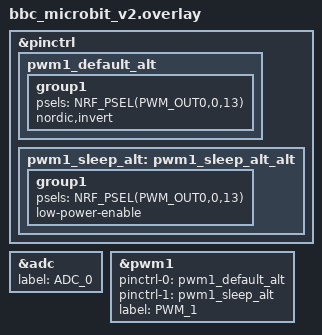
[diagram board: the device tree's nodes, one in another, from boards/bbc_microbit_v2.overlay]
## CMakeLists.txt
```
# SPDX-License-Identifier: Apache-2.0

cmake_minimum_required(VERSION 3.20.0)
find_package(Zephyr REQUIRED HINTS $ENV{ZEPHYR_BASE})
project(peripheral)


# Automatically include all .c files in the src directory
file(GLOB APP_SOURCES "src/*.c")

target_sources(app PRIVATE
  ${APP_SOURCES}
)
```

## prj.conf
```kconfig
# Increased stack due to settings API usage
CONFIG_SYSTEM_WORKQUEUE_STACK_SIZE=2048

CONFIG_BT=y
CONFIG_LOG=y
CONFIG_BT_SMP=y
CONFIG_BT_SIGNING=y
CONFIG_BT_PERIPHERAL=y
CONFIG_BT_DIS=y
CONFIG_BT_ATT_PREPARE_COUNT=5
CONFIG_BT_PRIVACY=y
CONFIG_BT_DEVICE_NAME="Fish Feeder"
CONFIG_BT_DEVICE_APPEARANCE=833
CONFIG_BT_DEVICE_NAME_DYNAMIC=y
CONFIG_BT_DEVICE_NAME_MAX=65

CONFIG_BT_KEYS_OVERWRITE_OLDEST=y
CONFIG_BT_SETTINGS=y
CONFIG_FLASH=y
CONFIG_FLASH_MAP=y
CONFIG_NVS=y
CONFIG_SETTINGS=y

CONFIG_GPIO=y

CONFIG_SERIAL=y
CONFIG_CONSOLE=y
CONFIG_UART_CONSOLE=y

CONFIG_NFCT_PINS_AS_GPIOS=y

CONFIG_CBPRINTF_FP_SUPPORT=y

CONFIG_PWM=y
CONFIG_ADC=y
CONFIG_NRFX_SAADC=y

CONFIG_DISPLAY=y
```

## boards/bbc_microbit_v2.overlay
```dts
&pinctrl {
    pwm1_default_alt: pwm1_default_alt {
        group1  {
            psels = <NRF_PSEL(PWM_OUT0,0,13)>;
            nordic,invert;
        };
    };
    pwm1_sleep_alt: pwm1_sleep_alt_alt {
        group1  {
            psels = <NRF_PSEL(PWM_OUT0,0,13)>;
            low-power-enable;
        };
    };
};

&adc {
	status = "okay";
    label = "ADC_0";
};

&pwm1 {
	status = "okay";
    pinctrl-0 = <&pwm1_default_alt>;
    pinctrl-1 = <&pwm1_sleep_alt>;
    pinctrl-names = "default", "sleep";

    label="PWM_1";
};
```

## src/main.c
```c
#include "pin_defs.h"
#include "ultrasonic.h"
#include <zephyr/kernel.h>
#include <zephyr/device.h>
#include <zephyr/drivers/gpio.h>
#include <stdio.h>
#include "info.h"
#include "timer.h"
#include "pwm.h"
#include "adc.h"
#include "display.h"
#include "ble.h"

#define THREAD_STACK_SIZE 1024  // Adjust based on usage
#define THREAD_PRIORITY 5       // Higher number = lower priority
#define ADC_THRESHOLD 100

K_THREAD_STACK_DEFINE(adc_thread_stack, THREAD_STACK_SIZE);
static struct k_thread adc_thread_data;

K_THREAD_STACK_DEFINE(timer_feed_thread_stack, THREAD_STACK_SIZE);
static struct k_thread timer_feed_thread_data;

K_THREAD_STACK_DEFINE(food_level_thread_stack, THREAD_STACK_SIZE);
static struct k_thread food_level_thread_data;

void adc_thread(void* p1, void* p2, void* p3) {
	bool has_pwm_lock = false;
	bool has_disp_lock = false;
	while (1) {
		int val = adcread();
		if (val > ADC_THRESHOLD) {
			// set duty to something
			// if (has_lock) {
			// 	pwm_set_duty((float)val / 4096.0f);
			// } else if (pwm_lock(100) == 0) {
			// 	has_lock = true;
			// 	pwm_set_duty((float)val / 4096.0f);
			// } else {
			// 	has_lock = false;
			// }
			if (!has_pwm_lock) {
				if (pwm_lock(100) == 0) {
					has_pwm_lock = true;
				}
			}
			if (has_pwm_lock) {
				float percentage = (float)val / 4096.0f;
				pwm_set_duty(percentage);

				if (!has_disp_lock) {
					if (display_lock() == 0) {
						has_disp_lock = true;
					}
				}
				if (has_disp_lock) {
					write_row_pattern((int)(percentage * 25));
				}
			}
		} else {
			// set duty to 0
			if (has_pwm_lock) {
				pwm_set_duty(0);
				pwm_unlock();
				has_pwm_lock = false;
			}
			if (has_disp_lock) {
				write_row_pattern(0);
				display_unlock();
				has_disp_lock = false;
			}
		}
		k_sleep(K_MSEC(100));
	}
}

void timer_feed_thread(void* p1, void* p2, void* p3) {
	info_t* info = get_info();
	while (1) {
		k_mutex_lock(info->mut, K_FOREVER);
		uint32_t cur_time = read_timer_s();
		uint32_t next_feed_time = info->_next_feed_timestamp_sec;
		uint32_t feed_dur = info->feed_duration_sec;
		// fprintf(stderr, "next feed time: %d, current time %d\n", next_feed_time, cur_time);
		k_mutex_unlock(info->mut);

		if (cur_time >= next_feed_time) {
			// feed
			if (pwm_lock(1) == 0) {
				fprintf(stderr, "Feeding for %d seconds\n", feed_dur);
				pwm_set_duty(0.5);
				k_sleep(K_SECONDS(feed_dur));
				pwm_set_duty(0);
				pwm_unlock();
			} else {
				fprintf(stderr, "timer feed:Failed to lock PWM\n");
				k_sleep(K_SECONDS(feed_dur));
			}

			k_mutex_lock(info->mut, K_FOREVER);
			info->_last_feed_timestamp_sec = cur_time;
			info->_next_feed_timestamp_sec = cur_time + info->feed_freq_sec;
			k_mutex_unlock(info->mut);
		}

		k_sleep(K_MSEC(100));
	}
}

void food_level_thread(void* p1, void* p2, void* p3) {
	info_t* info = get_info();
	while (1) {
		// check food level
		double distance = sample_sensors_distance_cm();
		fprintf(stderr, "Distance: %f\n", distance);

		k_mutex_lock(info->mut, K_FOREVER);
		info->is_food_low = distance >= 15.0;
		bt_gatt_notify(NULL, &custom_svc.attrs[4], &get_info()->is_food_low, 1);
		k_mutex_unlock(info->mut);

		k_sleep(K_SECONDS(3));
	}
}

int ble_main(void);

int main(void) {
	fprintf(stderr, "Hello, there!\n");
	k_sleep(K_MSEC(10)); // let the RTOS do its thing

	display_init();
	write_row_pattern(25);

	pwm_init();
	pwm_set_duty(0);

	ultrasonic_init();

	if (ble_init()) {
		fprintf(stderr, "Error initializing BLE\n");
		return -1;
	}
	fprintf(stderr, "BLE initialized\n");

	info_t* info = get_info();

	// Initialize the ADC
	if (adc_begin() != 0) {
		fprintf(stderr, "Error initializing ADC\n");
		return -1;
	}
	fprintf(stderr, "ADC initialized\n");

	k_thread_create(&adc_thread_data, adc_thread_stack,
		K_THREAD_STACK_SIZEOF(adc_thread_stack),
		adc_thread, NULL, NULL, NULL,
		THREAD_PRIORITY, 0, K_NO_WAIT);

	k_thread_create(&timer_feed_thread_data, timer_feed_thread_stack,
		K_THREAD_STACK_SIZEOF(timer_feed_thread_stack),
		timer_feed_thread, NULL, NULL, NULL,
		THREAD_PRIORITY, 0, K_NO_WAIT);

	k_thread_create(&food_level_thread_data, food_level_thread_stack,
		K_THREAD_STACK_SIZEOF(food_level_thread_stack),
		food_level_thread, NULL, NULL, NULL,
		THREAD_PRIORITY, 0, K_NO_WAIT);

	while (1) {
		// simulate counting down to feeding
		k_mutex_lock(info->mut, K_FOREVER);

		uint32_t cur_time = read_timer_s();
		uint32_t period = info->feed_freq_sec;

		info->next_feed_sec = info->_next_feed_timestamp_sec - cur_time;
		info->last_feed_sec = cur_time - info->_last_feed_timestamp_sec;

		float percentage = (float)info->last_feed_sec / (float)(info->next_feed_sec + info->last_feed_sec);

		k_mutex_unlock(info->mut);

		if (display_lock() == 0) {
			write_ring_pattern((int)(percentage * 16), 0, cur_time % 2);
			display_unlock();
		}
		// write_row_pattern(cur_time);

		k_sleep(K_MSEC(100));
	}

	while (1) {
		k_sleep(K_SECONDS(1));
	}

	return -1;
}
```

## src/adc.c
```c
#include <zephyr/drivers/adc.h>

/*
 * The internal voltage reference is 0.6V
 * The permissable gains are 1/6, 1/5, 1/4, 1/3, 1/2, 1, 2 and 4
 * If a gain of 1/5 is selected then the ADC range becomes 0 to 3V
 */

static const struct device* adc;

// Will read from analog input on P0.2 which is RING 0 on the microbit v2
#define ADC_PORT_BIT 2
struct adc_channel_cfg channel_cfg = {
	/* gain of 1/5 */
	.gain = ADC_GAIN_1_5,
	/* 0.6V reference */
	.reference = ADC_REF_INTERNAL,
	/* sample and hold time of 3us is the default (0 setting) on the NRF52833 */
	.acquisition_time = ADC_ACQ_TIME_DEFAULT,
	/* Channel 0 */
	.channel_id = 0,
	/* AIN0 is specified by setting input_positive to 0+1 i.e. an offset of 1  */
	/* This is as a result of the way the PSELP and PSELN registers work in the NRF52 series of devices */
	/* see page 375 of the NRF52 product specificatoin version : 4452_021 v1.3 */
	.input_positive = 1,
	/* Using single ended conversions */
	.differential = 0
};

int adc_begin() {
	int ret;
	// Configure the GPIO's
	adc = device_get_binding("ADC_0");
	if (adc == NULL) {
		fprintf(stderr, "Error acquiring ADC \n");
		return -1;
	}
	ret = adc_channel_setup(adc, &channel_cfg);
	if (ret < 0) {
		fprintf(stderr, "Error configuring ADC channel 0\n");
		return -2;
	}
	return 0;
}

static int16_t channel_0_data;  // This will hold the adc result

struct adc_sequence sequence = {
	/* This is a bitmask that tells the driver which channels to convert : bit n = 1 for channel n */
	.channels = (1 << 0),
	/* Where will the data be stored (could be an array if there are multiple channels to convert */
	.buffer = &channel_0_data,
	/* buffer size in bytes, not number of samples */
	.buffer_size = sizeof(channel_0_data),
	/* 12 bit resolution */
	.resolution = 12,
	/* nulls for the rest of the fields */
	.options = NULL,
	.calibrate = 0,
	.oversampling = 0,
};


int adcread() {
	int ret;
	ret = adc_read(adc, &sequence);
	return channel_0_data;
}
```

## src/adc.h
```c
int adc_begin();

int adcread();
```

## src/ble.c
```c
#include "ble.h"
#include "info.h"

#include <zephyr/types.h>
#include <stddef.h>
#include <string.h>
#include <errno.h>
#include <zephyr/sys/printk.h>
#include <zephyr/sys/byteorder.h>
#include <zephyr/kernel.h>

#include <zephyr/settings/settings.h>

#include <zephyr/bluetooth/bluetooth.h>
#include <zephyr/bluetooth/hci.h>
#include <zephyr/bluetooth/conn.h>
#include <zephyr/bluetooth/uuid.h>
#include <zephyr/bluetooth/gatt.h>
#include <zephyr/bluetooth/services/ias.h>
#include "cmd.h"

/* Custom Service Variables */
#define BT_UUID_CUSTOM_SERVICE_VAL \
	BT_UUID_128_ENCODE(0x12345678, 0x1234, 0x5678, 0x1234, 0x56789abcdef0)

static const struct bt_uuid_128 service_uuid = BT_UUID_INIT_128(
    BT_UUID_CUSTOM_SERVICE_VAL
);

#define BT_UUID_SETTINGS_STR_CHAR   BT_UUID_DECLARE_128(BT_UUID_128_ENCODE(0x12345678, 0x1234, 0x5678, 0x9ABC, 0xDEF012345679))
#define BT_UUID_CMD_CHAR            BT_UUID_DECLARE_128(BT_UUID_128_ENCODE(0x12345678, 0x1234, 0x5678, 0x9ABC, 0xDEF012345680))
#define BT_UUID_FOOD_NOTIFY_CHAR    BT_UUID_DECLARE_128(BT_UUID_128_ENCODE(0x12345678, 0x1234, 0x5678, 0x9ABC, 0xDEF012345681))

#define BUF_SIZE 512

static uint8_t* food_is_low;
static char read_settings_buffer[BUF_SIZE];
static uint8_t cmd_buffer[BUF_SIZE];

static ssize_t read_settings_callback(struct bt_conn* conn,
    const struct bt_gatt_attr* attr,
    void* buf, uint16_t len, uint16_t offset) {
    fprintf(stderr, "Received Read\n");
    info_to_buf_str(read_settings_buffer, BUF_SIZE);
    return bt_gatt_attr_read(conn, attr, buf, len, offset, read_settings_buffer, sizeof(read_settings_buffer));
}

static ssize_t write_cmd_callback(struct bt_conn* conn,
    const struct bt_gatt_attr* attr,
    const void* buf, uint16_t len, uint16_t offset,
    uint8_t flags) {
    if (offset + len > sizeof(cmd_buffer)) {
        return BT_GATT_ERR(BT_ATT_ERR_INVALID_OFFSET);
    }

    memcpy(cmd_buffer + offset, buf, len);

    // terminate strings
    if (offset + len + 1 >= BUF_SIZE) {
        cmd_buffer[BUF_SIZE - 1] = 0;
    } else {
        cmd_buffer[offset + len] = 0;
    }

    fprintf(stderr, "Received Write: %.*s\n", len, (char*)buf);

    char* orig_write_value = cmd_buffer;
    execute_command(cmd_buffer, BUF_SIZE);

    char** bruh = &cmd_buffer;
    *bruh = orig_write_value;

    return len;
}

// CCC callback function - will be called when notifications are enabled/disabled
static void food_notify_ccc_cfg_changed(const struct bt_gatt_attr* attr, uint16_t value) {
    bool notifications_enabled = (value == BT_GATT_CCC_NOTIFY);
    fprintf(stderr, "Food notifications %s\n", notifications_enabled ? "enabled" : "disabled");
}

static ssize_t read_food_notify(struct bt_conn* conn, const struct bt_gatt_attr* attr,
    void* buf, uint16_t len, uint16_t offset) {

    return bt_gatt_attr_read(conn, attr, buf, len, offset, food_is_low,
        sizeof(*food_is_low));
}

BT_GATT_SERVICE_DEFINE(custom_svc,
    BT_GATT_PRIMARY_SERVICE(&service_uuid),
    BT_GATT_CHARACTERISTIC(BT_UUID_SETTINGS_STR_CHAR, BT_GATT_CHRC_READ,
        BT_GATT_PERM_READ, read_settings_callback, NULL, NULL),
    BT_GATT_CHARACTERISTIC(BT_UUID_CMD_CHAR, BT_GATT_CHRC_WRITE,
        BT_GATT_PERM_WRITE, NULL, write_cmd_callback, cmd_buffer),
    BT_GATT_CHARACTERISTIC(BT_UUID_FOOD_NOTIFY_CHAR,
        BT_GATT_CHRC_READ | BT_GATT_CHRC_NOTIFY,
        BT_GATT_PERM_READ,
        read_food_notify, NULL, NULL),
    BT_GATT_CCC(food_notify_ccc_cfg_changed,
        BT_GATT_PERM_READ | BT_GATT_PERM_WRITE),
    );

static const struct bt_data ad[] = {
    BT_DATA_BYTES(BT_DATA_FLAGS, (BT_LE_AD_GENERAL | BT_LE_AD_NO_BREDR)),
    BT_DATA_BYTES(BT_DATA_UUID128_ALL, BT_UUID_CUSTOM_SERVICE_VAL),

};

static const struct bt_data sd[] = {
    BT_DATA(BT_DATA_NAME_COMPLETE, CONFIG_BT_DEVICE_NAME, sizeof(CONFIG_BT_DEVICE_NAME) - 1),
};

static void connected(struct bt_conn* conn, uint8_t err) {
    if (err) {
        fprintf(stderr, "Connection failed, err 0x%02x %s\n", err, bt_hci_err_to_str(err));
    } else {
        fprintf(stderr, "Connected\n");
    }
}

static void disconnected(struct bt_conn* conn, uint8_t reason) {
    fprintf(stderr, "Disconnected, reason 0x%02x %s\n", reason, bt_hci_err_to_str(reason));
}

BT_CONN_CB_DEFINE(conn_callbacks) = {
    .connected = connected,
    .disconnected = disconnected,
};

static void bt_ready(void) {
    int err;

    if (IS_ENABLED(CONFIG_SETTINGS)) {
        settings_load();
    }

    err = bt_le_adv_start(BT_LE_ADV_CONN_ONE_TIME, ad, ARRAY_SIZE(ad), sd, ARRAY_SIZE(sd));
    if (err) {
        fprintf(stderr, "Advertising failed to start (err %d)\n", err);
        return;
    }

    fprintf(stderr, "Advertising successfully started\n");
}

int ble_init(void) {
    int err = bt_enable(NULL);

    if (err) {
        return -1;
    }

    fprintf(stderr, "Bluetooth initialized\n");

    food_is_low = &get_info()->is_food_low;

    bt_ready();
    return 0;
}
```

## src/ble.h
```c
#include <zephyr/bluetooth/gatt.h>

extern const struct bt_gatt_service_static custom_svc;

int ble_init(void);
```

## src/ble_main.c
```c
// /* main.c - Application main entry point */

// /*
//  * Copyright (c) 2015-2016 Intel Corporation
//  *
//  * SPDX-License-Identifier: Apache-2.0
//  */

// #include <zephyr/types.h>
// #include <stddef.h>
// #include <string.h>
// #include <errno.h>
// #include <zephyr/sys/printk.h>
// #include <zephyr/sys/byteorder.h>
// #include <zephyr/kernel.h>

// #include <zephyr/settings/settings.h>

// #include <zephyr/bluetooth/bluetooth.h>
// #include <zephyr/bluetooth/hci.h>
// #include <zephyr/bluetooth/conn.h>
// #include <zephyr/bluetooth/uuid.h>
// #include <zephyr/bluetooth/gatt.h>
// #include <zephyr/bluetooth/services/bas.h>
// #include <zephyr/bluetooth/services/cts.h>
// #include <zephyr/bluetooth/services/hrs.h>
// #include <zephyr/bluetooth/services/ias.h>

//  /* Custom Service Variables */
// #define BT_UUID_CUSTOM_SERVICE_VAL \
// 	BT_UUID_128_ENCODE(0x12345678, 0x1234, 0x5678, 0x1234, 0x56789abcdef0)

// static const struct bt_uuid_128 vnd_uuid = BT_UUID_INIT_128(
// 	BT_UUID_CUSTOM_SERVICE_VAL);

// static const struct bt_uuid_128 vnd_enc_uuid = BT_UUID_INIT_128(
// 	BT_UUID_128_ENCODE(0x12345678, 0x1234, 0x5678, 0x1234, 0x56789abcdef1));

// static const struct bt_uuid_128 vnd_auth_uuid = BT_UUID_INIT_128(
// 	BT_UUID_128_ENCODE(0x12345678, 0x1234, 0x5678, 0x1234, 0x56789abcdef2));

// #define VND_MAX_LEN 20
// #define BT_HR_HEARTRATE_DEFAULT_MIN 90U
// #define BT_HR_HEARTRATE_DEFAULT_MAX 160U

// static uint8_t vnd_value[VND_MAX_LEN + 1] = { 'V', 'e', 'n', 'd', 'o', 'r' };
// static uint8_t vnd_auth_value[VND_MAX_LEN + 1] = { 'V', 'e', 'n', 'd', 'o', 'r' };
// static uint8_t vnd_wwr_value[VND_MAX_LEN + 1] = { 'V', 'e', 'n', 'd', 'o', 'r' };

// static ssize_t read_vnd(struct bt_conn* conn, const struct bt_gatt_attr* attr,
// 	void* buf, uint16_t len, uint16_t offset) {
// 	const char* value = attr->user_data;

// 	return bt_gatt_attr_read(conn, attr, buf, len, offset, value,
// 		strlen(value));
// }

// static ssize_t write_vnd(struct bt_conn* conn, const struct bt_gatt_attr* attr,
// 	const void* buf, uint16_t len, uint16_t offset,
// 	uint8_t flags) {
// 	uint8_t* value = attr->user_data;

// 	if (offset + len > VND_MAX_LEN) {
// 		return BT_GATT_ERR(BT_ATT_ERR_INVALID_OFFSET);
// 	}

// 	memcpy(value + offset, buf, len);
// 	value[offset + len] = 0;

// 	return len;
// }

// static uint8_t simulate_vnd;
// static uint8_t indicating;
// static struct bt_gatt_indicate_params ind_params;

// static void vnd_ccc_cfg_changed(const struct bt_gatt_attr* attr, uint16_t value) {
// 	simulate_vnd = (value == BT_GATT_CCC_INDICATE) ? 1 : 0;
// }

// static void indicate_cb(struct bt_conn* conn,
// 	struct bt_gatt_indicate_params* params, uint8_t err) {
// 	printk("Indication %s\n", err != 0U ? "fail" : "success");
// }

// static void indicate_destroy(struct bt_gatt_indicate_params* params) {
// 	printk("Indication complete\n");
// 	indicating = 0U;
// }

// #define VND_LONG_MAX_LEN 74
// static uint8_t vnd_long_value[VND_LONG_MAX_LEN + 1] = {
// 		  'V', 'e', 'n', 'd', 'o', 'r', ' ', 'd', 'a', 't', 'a', '1',
// 		  'V', 'e', 'n', 'd', 'o', 'r', ' ', 'd', 'a', 't', 'a', '2',
// 		  'V', 'e', 'n', 'd', 'o', 'r', ' ', 'd', 'a', 't', 'a', '3',
// 		  'V', 'e', 'n', 'd', 'o', 'r', ' ', 'd', 'a', 't', 'a', '4',
// 		  'V', 'e', 'n', 'd', 'o', 'r', ' ', 'd', 'a', 't', 'a', '5',
// 		  'V', 'e', 'n', 'd', 'o', 'r', ' ', 'd', 'a', 't', 'a', '6',
// 		  '.', ' ' };

// static ssize_t write_long_vnd(struct bt_conn* conn,
// 	const struct bt_gatt_attr* attr, const void* buf,
// 	uint16_t len, uint16_t offset, uint8_t flags) {
// 	uint8_t* value = attr->user_data;

// 	if (flags & BT_GATT_WRITE_FLAG_PREPARE) {
// 		return 0;
// 	}

// 	if (offset + len > VND_LONG_MAX_LEN) {
// 		return BT_GATT_ERR(BT_ATT_ERR_INVALID_OFFSET);
// 	}

// 	memcpy(value + offset, buf, len);
// 	value[offset + len] = 0;

// 	return len;
// }

// static const struct bt_uuid_128 vnd_long_uuid = BT_UUID_INIT_128(
// 	BT_UUID_128_ENCODE(0x12345678, 0x1234, 0x5678, 0x1234, 0x56789abcdef3));

// static struct bt_gatt_cep vnd_long_cep = {
// 	.properties = BT_GATT_CEP_RELIABLE_WRITE,
// };

// static int signed_value;

// static ssize_t read_signed(struct bt_conn* conn, const struct bt_gatt_attr* attr,
// 	void* buf, uint16_t len, uint16_t offset) {
// 	const char* value = attr->user_data;

// 	return bt_gatt_attr_read(conn, attr, buf, len, offset, value,
// 		sizeof(signed_value));
// }

// static ssize_t write_signed(struct bt_conn* conn, const struct bt_gatt_attr* attr,
// 	const void* buf, uint16_t len, uint16_t offset,
// 	uint8_t flags) {
// 	uint8_t* value = attr->user_data;

// 	if (offset + len > sizeof(signed_value)) {
// 		return BT_GATT_ERR(BT_ATT_ERR_INVALID_OFFSET);
// 	}

// 	memcpy(value + offset, buf, len);

// 	return len;
// }

// static const struct bt_uuid_128 vnd_signed_uuid = BT_UUID_INIT_128(
// 	BT_UUID_128_ENCODE(0x13345678, 0x1234, 0x5678, 0x1334, 0x56789abcdef3));

// static const struct bt_uuid_128 vnd_write_cmd_uuid = BT_UUID_INIT_128(
// 	BT_UUID_128_ENCODE(0x12345678, 0x1234, 0x5678, 0x1234, 0x56789abcdef4));

// static ssize_t write_without_rsp_vnd(struct bt_conn* conn,
// 	const struct bt_gatt_attr* attr,
// 	const void* buf, uint16_t len, uint16_t offset,
// 	uint8_t flags) {
// 	uint8_t* value = attr->user_data;

// 	if (!(flags & BT_GATT_WRITE_FLAG_CMD)) {
// 		/* Write Request received. Reject it since this Characteristic
// 		 * only accepts Write Without Response.
// 		 */
// 		return BT_GATT_ERR(BT_ATT_ERR_WRITE_REQ_REJECTED);
// 	}

// 	if (offset + len > VND_MAX_LEN) {
// 		return BT_GATT_ERR(BT_ATT_ERR_INVALID_OFFSET);
// 	}

// 	memcpy(value + offset, buf, len);
// 	value[offset + len] = 0;

// 	return len;
// }

// /* Vendor Primary Service Declaration */
// BT_GATT_SERVICE_DEFINE(vnd_svc,
// 	BT_GATT_PRIMARY_SERVICE(&vnd_uuid),
// 	BT_GATT_CHARACTERISTIC(&vnd_enc_uuid.uuid,
// 		BT_GATT_CHRC_READ | BT_GATT_CHRC_WRITE |
// 		BT_GATT_CHRC_INDICATE,
// 		BT_GATT_PERM_READ_ENCRYPT |
// 		BT_GATT_PERM_WRITE_ENCRYPT,
// 		read_vnd, write_vnd, vnd_value),
// 	BT_GATT_CCC(vnd_ccc_cfg_changed,
// 		BT_GATT_PERM_READ | BT_GATT_PERM_WRITE_ENCRYPT),
// 	BT_GATT_CHARACTERISTIC(&vnd_auth_uuid.uuid,
// 		BT_GATT_CHRC_READ | BT_GATT_CHRC_WRITE,
// 		BT_GATT_PERM_READ_AUTHEN |
// 		BT_GATT_PERM_WRITE_AUTHEN,
// 		read_vnd, write_vnd, vnd_auth_value),
// 	BT_GATT_CHARACTERISTIC(&vnd_long_uuid.uuid, BT_GATT_CHRC_READ |
// 		BT_GATT_CHRC_WRITE | BT_GATT_CHRC_EXT_PROP,
// 		BT_GATT_PERM_READ | BT_GATT_PERM_WRITE |
// 		BT_GATT_PERM_PREPARE_WRITE,
// 		read_vnd, write_long_vnd, &vnd_long_value),
// 	BT_GATT_CEP(&vnd_long_cep),
// 	BT_GATT_CHARACTERISTIC(&vnd_signed_uuid.uuid, BT_GATT_CHRC_READ |
// 		BT_GATT_CHRC_WRITE | BT_GATT_CHRC_AUTH,
// 		BT_GATT_PERM_READ | BT_GATT_PERM_WRITE,
// 		read_signed, write_signed, &signed_value),
// 	BT_GATT_CHARACTERISTIC(&vnd_write_cmd_uuid.uuid,
// 		BT_GATT_CHRC_WRITE_WITHOUT_RESP,
// 		BT_GATT_PERM_WRITE, NULL,
// 		write_without_rsp_vnd, &vnd_wwr_value),
// 	);

// static const struct bt_data ad[] = {
// 	BT_DATA_BYTES(BT_DATA_FLAGS, (BT_LE_AD_GENERAL | BT_LE_AD_NO_BREDR)),
// 	BT_DATA_BYTES(BT_DATA_UUID16_ALL,
// 			  BT_UUID_16_ENCODE(BT_UUID_HRS_VAL),
// 			  BT_UUID_16_ENCODE(BT_UUID_BAS_VAL),
// 			  BT_UUID_16_ENCODE(BT_UUID_CTS_VAL)),
// 	BT_DATA_BYTES(BT_DATA_UUID128_ALL, BT_UUID_CUSTOM_SERVICE_VAL),
// };

// static const struct bt_data sd[] = {
// 	BT_DATA(BT_DATA_NAME_COMPLETE, CONFIG_BT_DEVICE_NAME, sizeof(CONFIG_BT_DEVICE_NAME) - 1),
// };

// void mtu_updated(struct bt_conn* conn, uint16_t tx, uint16_t rx) {
// 	printk("Updated MTU: TX: %d RX: %d bytes\n", tx, rx);
// }

// static struct bt_gatt_cb gatt_callbacks = {
// 	.att_mtu_updated = mtu_updated
// };

// static void connected(struct bt_conn* conn, uint8_t err) {
// 	if (err) {
// 		printk("Connection failed, err 0x%02x %s\n", err, bt_hci_err_to_str(err));
// 	} else {
// 		printk("Connected\n");
// 	}
// }

// static void disconnected(struct bt_conn* conn, uint8_t reason) {
// 	printk("Disconnected, reason 0x%02x %s\n", reason, bt_hci_err_to_str(reason));
// }

// static void alert_stop(void) {
// 	printk("Alert stopped\n");
// }

// static void alert_start(void) {
// 	printk("Mild alert started\n");
// }

// static void alert_high_start(void) {
// 	printk("High alert started\n");
// }

// BT_CONN_CB_DEFINE(conn_callbacks) = {
// 	.connected = connected,
// 	.disconnected = disconnected,
// };

// BT_IAS_CB_DEFINE(ias_callbacks) = {
// 	.no_alert = alert_stop,
// 	.mild_alert = alert_start,
// 	.high_alert = alert_high_start,
// };

// static void bt_ready(void) {
// 	int err;

// 	printk("Bluetooth initialized\n");

// 	if (IS_ENABLED(CONFIG_SETTINGS)) {
// 		settings_load();
// 	}

// 	err = bt_le_adv_start(BT_LE_ADV_CONN_ONE_TIME, ad, ARRAY_SIZE(ad), sd, ARRAY_SIZE(sd));
// 	if (err) {
// 		printk("Advertising failed to start (err %d)\n", err);
// 		return;
// 	}

// 	printk("Advertising successfully started\n");
// }

// static void auth_passkey_display(struct bt_conn* conn, unsigned int passkey) {
// 	char addr[BT_ADDR_LE_STR_LEN];

// 	bt_addr_le_to_str(bt_conn_get_dst(conn), addr, sizeof(addr));

// 	printk("Passkey for %s: %06u\n", addr, passkey);
// }

// static void auth_cancel(struct bt_conn* conn) {
// 	char addr[BT_ADDR_LE_STR_LEN];

// 	bt_addr_le_to_str(bt_conn_get_dst(conn), addr, sizeof(addr));

// 	printk("Pairing cancelled: %s\n", addr);
// }

// static struct bt_conn_auth_cb auth_cb_display = {
// 	.passkey_display = auth_passkey_display,
// 	.passkey_entry = NULL,
// 	.cancel = auth_cancel,
// };

// static void bas_notify(void) {
// 	uint8_t battery_level = bt_bas_get_battery_level();

// 	battery_level--;

// 	if (!battery_level) {
// 		battery_level = 100U;
// 	}

// 	bt_bas_set_battery_level(battery_level);
// }

// static uint8_t bt_heartrate = BT_HR_HEARTRATE_DEFAULT_MIN;

// static void hrs_notify(void) {
// 	/* Heartrate measurements simulation */
// 	bt_heartrate++;
// 	if (bt_heartrate == BT_HR_HEARTRATE_DEFAULT_MAX) {
// 		bt_heartrate = BT_HR_HEARTRATE_DEFAULT_MIN;
// 	}

// 	bt_hrs_notify(bt_heartrate);
// }

// /**
//  * variable to hold reference milliseconds to epoch when device booted
//  * this is only for demo purpose, for more precise synchronization please
//  * review clock_settime API implementation.
//  */
// static int64_t unix_ms_ref;
// static bool cts_notification_enabled;

// void bt_cts_notification_changed(bool enabled) {
// 	cts_notification_enabled = enabled;
// }

// int bt_cts_cts_time_write(struct bt_cts_time_format* cts_time) {
// 	int err;
// 	int64_t unix_ms;

// 	if (IS_ENABLED(CONFIG_BT_CTS_HELPER_API)) {
// 		err = bt_cts_time_to_unix_ms(cts_time, &unix_ms);
// 		if (err) {
// 			return err;
// 		}
// 	} else {
// 		return -ENOTSUP;
// 	}

// 	/* recalculate reference value */
// 	unix_ms_ref = unix_ms - k_uptime_get();
// 	return 0;
// }

// int bt_cts_fill_current_cts_time(struct bt_cts_time_format* cts_time) {
// 	int64_t unix_ms = unix_ms_ref + k_uptime_get();

// 	if (IS_ENABLED(CONFIG_BT_CTS_HELPER_API)) {
// 		return bt_cts_time_from_unix_ms(cts_time, unix_ms);
// 	} else {
// 		return -ENOTSUP;
// 	}
// }

// const struct bt_cts_cb cts_cb = {
// 	.notification_changed = bt_cts_notification_changed,
// 	.cts_time_write = bt_cts_cts_time_write,
// 	.fill_current_cts_time = bt_cts_fill_current_cts_time,
// };

// static int bt_hrs_ctrl_point_write(uint8_t request) {
// 	printk("HRS Control point request: %d\n", request);
// 	if (request != BT_HRS_CONTROL_POINT_RESET_ENERGY_EXPANDED_REQ) {
// 		return -ENOTSUP;
// 	}

// 	bt_heartrate = BT_HR_HEARTRATE_DEFAULT_MIN;
// 	return 0;
// }

// static struct bt_hrs_cb hrs_cb = {
// 	.ctrl_point_write = bt_hrs_ctrl_point_write,
// };

// int ble_main(void) {
// 	struct bt_gatt_attr* vnd_ind_attr;
// 	char str[BT_UUID_STR_LEN];
// 	int err;

// 	err = bt_enable(NULL);
// 	if (err) {
// 		printk("Bluetooth init failed (err %d)\n", err);
// 		return 0;
// 	}

// 	bt_ready();
// 	bt_cts_init(&cts_cb);
// 	bt_hrs_cb_register(&hrs_cb);

// 	bt_gatt_cb_register(&gatt_callbacks);
// 	bt_conn_auth_cb_register(&auth_cb_display);

// 	vnd_ind_attr = bt_gatt_find_by_uuid(vnd_svc.attrs, vnd_svc.attr_count,
// 		&vnd_enc_uuid.uuid);
// 	bt_uuid_to_str(&vnd_enc_uuid.uuid, str, sizeof(str));
// 	printk("Indicate VND attr %p (UUID %s)\n", vnd_ind_attr, str);

// 	/* Implement notification. At the moment there is no suitable way
// 	 * of starting delayed work so we do it here
// 	 */
// 	while (1) {
// 		k_sleep(K_SECONDS(1));

// 		/* Current time update notification example
// 		 * For testing purposes, we send a manual update notification every second.
// 		 * In production `bt_cts_send_notification` should only be used when time is changed
// 		 */
// 		if (cts_notification_enabled) {
// 			bt_cts_send_notification(BT_CTS_UPDATE_REASON_MANUAL);
// 		}
// 		/* Heartrate measurements simulation */
// 		hrs_notify();

// 		/* Battery level simulation */
// 		bas_notify();

// 		/* Vendor indication simulation */
// 		if (simulate_vnd && vnd_ind_attr) {
// 			if (indicating) {
// 				continue;
// 			}

// 			ind_params.attr = vnd_ind_attr;
// 			ind_params.func = indicate_cb;
// 			ind_params.destroy = indicate_destroy;
// 			ind_params.data = &indicating;
// 			ind_params.len = sizeof(indicating);

// 			if (bt_gatt_indicate(NULL, &ind_params) == 0) {
// 				indicating = 1U;
// 			}
// 		}
// 	}
// 	return 0;
// }



// // 
```

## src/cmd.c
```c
#include "cmd.h"
#include "info.h"
#include <stdio.h>
#include <stdlib.h>
#include <string.h>

#define BUF_SIZE 512

// function prototype because the string.h header doesn't have it enabled for
// some reason
char* strsep(char**, const char*);

void execute_command(char* cmd, size_t cmd_size) {
    char* password;
    info_t* info = get_info();

    password = strsep(&cmd, " ");
    if (!password || strcmp(password, "stephen")) {
        fprintf(stderr, "wrong password!\n");
        return;
    }

    char* action = strsep(&cmd, " ");
    if (!action) {
        fprintf(stderr, "no action!\n");
        return;
    } else if (!strcmp(action, "freq")) {
        char* new_freq_str = strsep(&cmd, " ");
        int new_freq = atoi(new_freq_str);

        if (new_freq <= 0) {
            return;
        }

        k_mutex_lock(info->mut, K_FOREVER);
        info->feed_freq_sec = new_freq;
        info->_next_feed_timestamp_sec = info->_last_feed_timestamp_sec + info->feed_freq_sec;
        k_mutex_unlock(info->mut);
        return;
    } else if (!strcmp(action, "dur")) {
        char* new_dur_str = strsep(&cmd, " ");
        int new_dur = atoi(new_dur_str);

        if (new_dur <= 0 || new_dur >= info->feed_freq_sec) {
            return;
        }

        k_mutex_lock(info->mut, K_FOREVER);
        info->feed_duration_sec = new_dur;
        k_mutex_unlock(info->mut);
        return;
    }
}
```

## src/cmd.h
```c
#include <stddef.h>

void execute_command(char* cmd, size_t cmd_size);
```

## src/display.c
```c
/*
 * Copyright (c) 2021, Nordic Semiconductor ASA
 *
 * SPDX-License-Identifier: Apache-2.0
 */

#include <zephyr/kernel.h>
#include <zephyr/sys/printk.h>
#include <zephyr/drivers/display.h>
#include <string.h>
#include "display.h"

#define PIXEL_BIT(idx, val)  (val ? BIT(idx) : 0)
#define PIXEL_MASK(...)      (FOR_EACH_IDX(PIXEL_BIT, (|), __VA_ARGS__))

static struct display_capabilities caps;
uint8_t display_buf[5];
static const struct display_buffer_descriptor buf_desc = {
	.buf_size = sizeof(display_buf),
	.width = 5,
	.height = 5,
	.pitch = 8,
};

const struct device* dev;

static struct k_mutex display_mutex;

int display_lock(void) {
	k_mutex_lock(&display_mutex, K_NO_WAIT);
}

void display_unlock(void) {
	k_mutex_unlock(&display_mutex);
}

int display_update(void) {
	int ret;
	ret = display_write(dev, 0, 0, &buf_desc, display_buf);
	if (ret < 0) {
		fprintf(stderr, "display_write failed: %u/%d\n",
			__LINE__, ret);
		return ret;
	}

	ret = display_blanking_off(dev);
	if (ret < 0) {
		fprintf(stderr, "display_blanking_off failed: %u/%d\n",
			__LINE__, ret);
		return ret;
	}

	return 0;
}

int display_init(void) {
	k_mutex_init(&display_mutex);

	int ret;
	dev = DEVICE_DT_GET_ONE(nordic_nrf_led_matrix);

	if (!dev) {
		fprintf(stderr, "Display device not ready\n");
		return 0;
	}

	display_get_capabilities(dev, &caps);
	if (!(caps.supported_pixel_formats & PIXEL_FORMAT_MONO01)) {
		fprintf(stderr, "Expected pixel format not supported\n");
		return 0;
	}

	ret = display_set_pixel_format(dev, PIXEL_FORMAT_MONO01);
	if (ret < 0) {
		fprintf(stderr, "display_set_pixel_format failed: %u/%d\n",
			__LINE__, ret);
	}

	ret = display_set_brightness(dev, 0x7F);
	if (ret < 0) {
		fprintf(stderr, "display_set_brightness failed: %u/%d\n",
			__LINE__, ret);
	}

	fprintf(stderr, "Initialized display\n");

	display_buf[0] = 0b00011111;
	display_buf[1] = 0b00011111;
	display_buf[2] = 0b00011111;
	display_buf[3] = 0b00011111;
	display_buf[4] = 0b00011111;

	display_update();
	return 0;
}

void write_ring_pattern(uint8_t outer_ring, uint8_t inner_ring, bool center) {
	memset(display_buf, 0, sizeof(display_buf)); // Clear buffer

	// Define outer ring LED positions (clockwise order)
	const uint8_t outer_ring_positions[16][2] = {
		{0,0}, {0,1}, {0,2}, {0,3}, {0,4}, {1,4}, {2,4}, {3,4},
		{4,4}, {4,3}, {4,2}, {4,1}, {4,0}, {3,0}, {2,0}, {1,0}
	};

	// Define inner ring LED positions (clockwise order)
	const uint8_t inner_ring_positions[8][2] = {
		{1,1}, {1,2}, {1,3}, {2,3}, {3,3}, {3,2}, {3,1}, {2,1}
	};

	// Light up outer ring LEDs
	for (uint8_t i = 0; i < outer_ring && i < 16; i++) {
		uint8_t row = outer_ring_positions[i][0];
		uint8_t col = outer_ring_positions[i][1];
		display_buf[row] |= (1 << col);
	}

	// Light up inner ring LEDs
	for (uint8_t i = 0; i < inner_ring && i < 8; i++) {
		uint8_t row = inner_ring_positions[i][0];
		uint8_t col = inner_ring_positions[i][1];
		display_buf[row] |= (1 << col);
	}

	// Light up center LED if requested
	if (center) {
		display_buf[2] |= (1 << 2);
	}

	display_update();
}

void write_row_pattern(uint8_t n) {
	// Ensure n is within the valid range
	if (n > 25) {
		n = 25;
	}

	// Clear the display buffer
	memset(display_buf, 0, sizeof(display_buf));

	// Set LEDs in row-major order
	for (int i = 0; i < n; i++) {
		int row = i / 5;  // Determine the row (0 to 4)
		int col = i % 5;  // Determine the column (0 to 4)
		display_buf[row] |= (1 << col);  // Set the corresponding bit to 1
	}

	display_update();
}
```

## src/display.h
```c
#include <stdint.h>

extern uint8_t display_buf[5];

int display_update(void);

int display_init(void);

void write_ring_pattern(uint8_t outer_ring, uint8_t inner_ring, bool center);

void write_row_pattern(uint8_t n);

int display_lock(void);

void display_unlock(void);
```

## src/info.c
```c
#include "info.h"
#include <string.h>

K_MUTEX_DEFINE(my_mutex);

static info_t fish_info = {
    5, // once every 5 seconds
    2, // spin for 5 seconds
    0, // haven't fed yet
    0, // haven't fed yet
    5, // will feed in 5 secocnds
    5, // will feed in 5 seconds
    0, // assume food isn't low for now
    &my_mutex
};

void info_to_buf_str(char* str_buf, uint32_t buf_size) {
    k_mutex_lock(fish_info.mut, K_FOREVER);

    // TODO: change the %d formatter to appropriate value for uint32_t
    const char* format_str =
        "Feed frequency (sec): %d\n"
        "Feed duration (sec): %d\n"
        "Last feed (sec): %d\n"
        "Next feed (sec): %d\n"
        "Is food low?: %s\n";

    char* food_level_str = fish_info.is_food_low ? "Yes" : "No";
    snprintf(str_buf, buf_size, format_str, fish_info.feed_freq_sec, fish_info.feed_duration_sec, fish_info.last_feed_sec, fish_info.next_feed_sec, food_level_str);

    k_mutex_unlock(fish_info.mut);
}

// i'm pretty sure we are on a single core system, so
info_t* get_info(void) {
    return &fish_info;
}
```

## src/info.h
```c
#include <stdint.h>
#include <zephyr/kernel.h>

typedef struct {
    uint32_t feed_freq_sec; // how often to feed (sec)
    uint32_t feed_duration_sec; // how long to feed for (sec)
    uint32_t _last_feed_timestamp_sec; // timestamp of last feeding
    uint32_t last_feed_sec; // how many seconds ago the last feeding was
    uint32_t _next_feed_timestamp_sec; // timestamp of next feeding
    uint32_t next_feed_sec; // in how many seconds will the next feeding occur
    uint8_t is_food_low; // whether food is low (boolean)
    struct k_mutex* mut; // kms this is needed for race conditions
} info_t;

void info_to_buf_str(char* str_buf, uint32_t buf_size);

info_t* get_info(void);
```

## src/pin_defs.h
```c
#pragma once

#define GPIO_PORT_0 DT_NODELABEL(gpio0)
#define GPIO_PORT_1 DT_NODELABEL(gpio1)

#define EDGE_P0_DEV DEVICE_DT_GET(DT_NODELABEL(gpio0))
#define EDGE_P1_DEV DEVICE_DT_GET(DT_NODELABEL(gpio0))
#define EDGE_P2_DEV DEVICE_DT_GET(DT_NODELABEL(gpio0))
#define EDGE_P3_DEV DEVICE_DT_GET(DT_NODELABEL(gpio0))
#define EDGE_P4_DEV DEVICE_DT_GET(DT_NODELABEL(gpio0))
#define EDGE_P5_DEV DEVICE_DT_GET(DT_NODELABEL(gpio0))
#define EDGE_P7_DEV DEVICE_DT_GET(DT_NODELABEL(gpio0))
#define EDGE_P8_DEV DEVICE_DT_GET(DT_NODELABEL(gpio0))
#define EDGE_P9_DEV DEVICE_DT_GET(DT_NODELABEL(gpio0))
#define EDGE_P10_DEV DEVICE_DT_GET(DT_NODELABEL(gpio0))
#define EDGE_P11_DEV DEVICE_DT_GET(DT_NODELABEL(gpio0))
#define EDGE_P12_DEV DEVICE_DT_GET(DT_NODELABEL(gpio0))
#define EDGE_P13_DEV DEVICE_DT_GET(DT_NODELABEL(gpio0))
#define EDGE_P14_DEV DEVICE_DT_GET(DT_NODELABEL(gpio0))
#define EDGE_P15_DEV DEVICE_DT_GET(DT_NODELABEL(gpio0))
#define EDGE_P19_DEV DEVICE_DT_GET(DT_NODELABEL(gpio0))

#define EDGE_P6_DEV DEVICE_DT_GET(DT_NODELABEL(gpio1))
#define EDGE_P16_DEV DEVICE_DT_GET(DT_NODELABEL(gpio1))
#define EDGE_P20_DEV DEVICE_DT_GET(DT_NODELABEL(gpio1))

#define EDGE_P0_IDX 2
#define EDGE_P1_IDX 3
#define EDGE_P2_IDX 4
#define EDGE_P3_IDX 31
#define EDGE_P4_IDX 28
#define EDGE_P5_IDX 14
#define EDGE_P6_IDX 5
#define EDGE_P7_IDX 11
#define EDGE_P8_IDX 10
#define EDGE_P9_IDX 9
#define EDGE_P10_IDX 30
#define EDGE_P11_IDX 23
#define EDGE_P12_IDX 12
#define EDGE_P13_IDX 17
#define EDGE_P14_IDX 1
#define EDGE_P15_IDX 13
#define EDGE_P16_IDX 2
#define EDGE_P19_IDX 26
#define EDGE_P20_IDX 0
```
